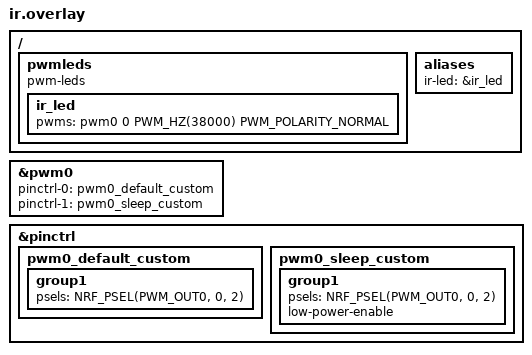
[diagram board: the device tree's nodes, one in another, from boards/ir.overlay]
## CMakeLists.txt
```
cmake_minimum_required(VERSION 3.20.0)
find_package(Zephyr REQUIRED HINTS $ENV{ZEPHYR_BASE})

project(node)

target_include_directories(app PRIVATE lib)

target_sources(app PRIVATE
    src/main.c
    lib/thread/thread.c
    lib/battery/battery.c
)
target_sources_ifdef(CONFIG_BLINKY app PRIVATE lib/blinky/blinky.c)
target_sources_ifdef(CONFIG_THREAD_STATUS_LED app PRIVATE lib/thread_status_led/thread_status_led.c)
target_sources_ifdef(CONFIG_BLINKY_THREAD app PRIVATE lib/blinky_thread/blinky_thread.c)

if(CONFIG_IR_VOLTAS OR CONFIG_IR_TECO)
    target_sources(app PRIVATE lib/ir/ir.c)
endif()

target_sources_ifdef(CONFIG_IR_VOLTAS app PRIVATE lib/ir/voltas.c)
target_sources_ifdef(CONFIG_IR_TECO app PRIVATE lib/ir/teco.c)
```

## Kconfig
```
mainmenu "Things Node"

config BLINKY
	bool "Enable blinky test mode"
	default n

config THREAD_HOSTNAME
	string "SRP hostname to register on the Thread network"
	default "thing"
	help
	  Registered via SRP once attached, so this device becomes
	  reachable as <hostname>.local from your LAN instead of needing
	  to know its Thread-assigned IPv6 address.

config THREAD_ANNOUNCE_ADDR
	string "IPv6 address to UDP-announce addresses to (debug)"
	default "fd2c:6656:1f1a:34af:4a4d:7eff:feed:5301"
	help
	  Every non-link-local IPv6 address this device gets is sent as a
	  plain UDP text message here whenever it changes - lets you
	  discover the node's reachable address without needing console
	  access. Defaults to hermes; override per build type, or set to
	  "" to disable.

config THREAD_ANNOUNCE_PORT
	int "UDP port for address announce"
	default 5555

config THING_CAPS
	string "Capability set advertised in the SRP service's TXT record"
	default ""
	help
	  Comma-separated capability tags (e.g. "ac_climate,battery"),
	  published as a single "caps" key in the _coap._udp SRP service's
	  TXT record. Lets a generic Home Assistant integration discover
	  what a given node actually supports and create the matching
	  entities - a node can declare more than one (e.g. a future board
	  mixing a PIR with a temp/humidity sensor: "pir,temp,humidity").
	  Set per build variant's conf fragment, not here - "" means no
	  capability declared.

config THING_CONFIG
	string "Extra per-node config, advertised in the SRP service's TXT record"
	default ""
	help
	  Comma-separated key=value pairs (e.g. "swing=v"), published as a
	  "config" key in the _coap._udp SRP service's TXT record - separate
	  from CONFIG_THING_CAPS on purpose: caps says which entity platforms
	  a node needs (drives PLATFORMS_BY_CAP on the HA side), this says how
	  an already-declared capability should behave for this specific
	  physical unit (e.g. which swing axis a real motor exists for, since
	  two nodes can both declare "ac_climate" but only one has a vertical
	  swing motor and the other only horizontal). Set per build variant's
	  conf fragment, not here - "" means no extra config.

config THREAD_STATUS_LED
	bool "RGB LED indicates Thread attach status"
	default y
	help
	  Blinks the onboard RGB LED red every 2s while attaching to
	  Thread (gives up after 60s to save battery), then solid blue
	  for 3s once attached. On by default for every build that has
	  Thread enabled (i.e. everything except CONFIG_BLINKY); disable
	  per build type in its conf fragment if not wanted.

config BLINKY_THREAD
	bool "Enable blinky+Thread test profile"
	default n
	help
	  Debug RGB LED control over Thread CoAP (POST /led) — on/off/
	  color. Unlike CONFIG_BLINKY, this runs alongside Thread rather
	  than blocking forever.

menu "IR Dialect"

config IR_VOLTAS
	bool "Voltas AC"
	default n
	help
	  Enable Voltas AC IR dialect.

config IR_TECO
	bool "Teco AC"
	default n
	help
	  Enable Teco AC IR dialect.

endmenu

source "Kconfig.zephyr"
```

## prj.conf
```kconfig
CONFIG_BUILD_OUTPUT_UF2=y

# OpenThread - Sleepy End Device (present on every node by default)
CONFIG_NETWORKING=y
CONFIG_NET_L2_OPENTHREAD=y
CONFIG_OPENTHREAD_MTD=y
CONFIG_OPENTHREAD_MTD_SED=y
CONFIG_OPENTHREAD_POLL_PERIOD=500
CONFIG_OPENTHREAD_MANUAL_START=y
CONFIG_OPENTHREAD_COAP=y
CONFIG_NET_IPV6=y
CONFIG_NET_UDP=y
CONFIG_NET_SOCKETS=y
CONFIG_OPENTHREAD_SLAAC=y
CONFIG_OPENTHREAD_SRP_CLIENT=y

# Reboot on any unrecoverable fault (stack overflow, hard fault, etc.)
# instead of Zephyr's default silent halt. Without this, any crash is a
# permanent hang requiring a manual power cycle - no watchdog either, so
# there's currently zero self-recovery on this node.
CONFIG_RESET_ON_FATAL_ERROR=y

# Power management - CONFIG_PM (system-level) removed 2026-08-16. nRF52 never
# selects HAS_PM (see soc/nordic/nrf52/Kconfig) - CONFIG_PM is silently forced
# back to n on this SoC regardless of this file, which is exactly the
# "assigned y, but got n" Kconfig warning that flagged this. Confirmed by
# measurement too: console-off + dropping CONFIG_PM only moved idle draw from
# ~8mA to 7.44mA, nowhere near the µA range PM would have implied if it worked.
#
# Real culprit: this board's onboard QSPI NOR flash (p25q16h, see
# node/boards/xiao_ble_nrf52840.overlay) is unused by this app (settings live
# on internal flash - see pm_static.yml) but stays powered/active by default.
# CONFIG_PM_DEVICE_RUNTIME is independent of CONFIG_PM/HAS_PM - it's the
# explicit get/put-refcounted path, not the idle-triggered one - and the
# nrf_qspi_nor driver already calls it around every access + implements a
# real suspend (enter deep-power-down, pinctrl sleep state). Combined with
# the `zephyr,pm-device-runtime-auto` DT property on the flash node, it
# should settle into DPD after the one-time init access and stay there.
CONFIG_PM_DEVICE=y
CONFIG_PM_DEVICE_RUNTIME=y

# No physical console is ever connected to this node (reverted early in the
# project) - CONFIG_PRINTK=y was still keeping the UART peripheral powered
# for a console nothing listens to. Nordic's own power-optimization guide
# measures this at ~470uA average just for that - pure waste here.
# Also disable the console subsystem itself (board default still wires it to
# a UART device) - otherwise it dangles a reference to the now-gone UART
# device at link time.a
CONFIG_SERIAL=n
CONFIG_CONSOLE=n
CONFIG_UART_CONSOLE=n

# 2026-08-16: the above three did NOT touch the real console path on this
# board. xiao_ble's devicetree wires `zephyr,console` to a USB CDC-ACM
# virtual UART, not a physical one (boards/common/usb/cdc_acm_serial.dtsi) -
# a separate subsystem gated by different Kconfig, defaulted on regardless of
# CONFIG_SERIAL/CONSOLE: `USB_DEVICE_STACK_NEXT` and
# `CDC_ACM_SERIAL_INITIALIZE_AT_BOOT` both `default y if !MCUBOOT` (see
# boards/common/usb/Kconfig.cdc_acm_serial.defconfig), and this build has no
# MCUboot. So the full USB device stack + its thread + the CDC-ACM class have
# been running through every measurement so far (~8mA, then 7.44mA, then
# 7.45mA) completely unaffected by any fix above - this is very likely the
# real dominant draw, not QSPI. Explicit override, since a plain default
# can't be beaten any other way:
CONFIG_USB_DEVICE_STACK_NEXT=n
CONFIG_CDC_ACM_SERIAL_INITIALIZE_AT_BOOT=n

# Stack / heap for networking
CONFIG_MAIN_STACK_SIZE=4096
CONFIG_SYSTEM_WORKQUEUE_STACK_SIZE=2048
CONFIG_HEAP_MEM_POOL_SIZE=8192

# Battery voltage over CoAP GET /battery - see node/lib/battery/battery.c
# and node/boards/xiao_ble_nrf52840.overlay for the VDD-as-battery ADC setup.
CONFIG_ADC=y

# OTA firmware updates via mcumgr, over UDP - rides straight over the
# Thread mesh's existing IPv6 connectivity (see hub/docs/border-router-
# native.md), no BLE/USB proximity needed. IPv6-only: this node has no
# IPv4 stack, and CONFIG_MCUMGR_TRANSPORT_UDP_IPV4 depends on CONFIG_NET_IPV4
# so it's already forced off without needing to say so here. img_mgmt talks
# to MCUboot's slot0/slot1 (see node/boards/mcuboot_partitions.overlay);
# os_mgmt is what provides the "reset" command used to trigger the
# slot swap after a test image is uploaded.
CONFIG_ZCBOR=y
CONFIG_STREAM_FLASH=y
CONFIG_MCUMGR=y
CONFIG_MCUMGR_TRANSPORT_UDP=y
CONFIG_MCUMGR_TRANSPORT_UDP_IPV6=y
CONFIG_IMG_MANAGER=y
CONFIG_MCUMGR_GRP_IMG=y
CONFIG_MCUMGR_GRP_OS=y
```

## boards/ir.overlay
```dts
/ {
	pwmleds {
		compatible = "pwm-leds";
		ir_led: ir_led {
			pwms = <&pwm0 0 PWM_HZ(38000) PWM_POLARITY_NORMAL>;
		};
	};

	aliases {
		ir-led = &ir_led;
	};
};

&pwm0 {
	status = "okay";
	pinctrl-0 = <&pwm0_default_custom>;
	pinctrl-1 = <&pwm0_sleep_custom>;
	pinctrl-names = "default", "sleep";
};

&pinctrl {
	pwm0_default_custom: pwm0_default_custom {
		group1 {
			psels = <NRF_PSEL(PWM_OUT0, 0, 2)>;
		};
	};

	pwm0_sleep_custom: pwm0_sleep_custom {
		group1 {
			psels = <NRF_PSEL(PWM_OUT0, 0, 2)>;
			low-power-enable;
		};
	};
};
```

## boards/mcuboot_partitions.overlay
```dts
/*
 * MCUboot-ready flash layout, shared by both the app image and the mcuboot
 * image itself (wired in via node/sysbuild/CMakeLists.txt) - both need the
 * same boot_partition/slot0_partition/slot1_partition nodelabels to agree
 * on where things physically live.
 *
 * Replaces the board's default single-image layout (sized for the factory
 * Adafruit UF2 bootloader - see nrf52840_partition_uf2_sdv7.dtsi in the
 * Zephyr tree) with the standard MCUboot layout used elsewhere in the
 * Zephyr tree for a bare nRF52840 (dts/vendor/nordic/nrf52840_partition.dtsi,
 * same numbers): mcuboot + two equal app slots for swap-with-revert OTA +
 * storage. This node is only ever flashed via SWD now, so there's no
 * remaining reason to preserve compatibility with the factory bootloader's
 * layout or its UF2 partition.
 *
 * Sizing: two 0x76000 (472KB) slots vs. the current single-image firmware's
 * actual flash usage of ~247KB (see PROGRESS.md /
 * arm-zephyr-eabi-size on a real build) - just under 2x headroom per slot
 * for growth.
 */
/ {
	chosen {
		/* Board default points this at the old single "code_partition",
		 * which /delete-node/ below removes along with the rest of the
		 * old layout - the app now boots from slot0, not directly from
		 * a fixed spot past a SoftDevice-shaped gap.
		 */
		zephyr,code-partition = &slot0_partition;
	};
};

&flash0 {
	/delete-node/ partitions;

	partitions {
		compatible = "fixed-partitions";
		#address-cells = <1>;
		#size-cells = <1>;

		boot_partition: partition@0 {
			label = "mcuboot";
			reg = <0x00000000 0x0000C000>;
			read-only;
		};

		slot0_partition: partition@c000 {
			label = "image-0";
			reg = <0x0000C000 0x00076000>;
		};

		slot1_partition: partition@82000 {
			label = "image-1";
			reg = <0x00082000 0x00076000>;
		};

		storage_partition: partition@f8000 {
			label = "storage";
			reg = <0x000F8000 0x00008000>;
		};
	};
};
```

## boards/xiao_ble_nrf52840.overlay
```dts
/*
 * The onboard QSPI NOR flash (p25q16h) is unused by this app - the
 * settings_storage partition lives on internal flash (see the board's
 * pm_static.yml). Left at its power-on default it just sits there powered
 * and active, drawing current for nothing. This DT property is what actually
 * triggers pm_device_runtime_enable() for it after init (see
 * include/zephyr/pm/device.h's DT_PROP_OR(..., zephyr_pm_device_runtime_auto)
 * check in kernel/device.c) - the driver (drivers/flash/nrf_qspi_nor.c)
 * already calls pm_device_runtime_get()/put_async() around every access and
 * implements a real suspend (deep-power-down + pinctrl sleep state), it just
 * needs runtime PM switched on for this instance. Requires
 * CONFIG_PM_DEVICE=y + CONFIG_PM_DEVICE_RUNTIME=y in prj.conf.
 */
&p25q16h {
	zephyr,pm-device-runtime-auto;
};

/*
 * Battery voltage. This node's coin cell is wired directly to 3V3/GND (no
 * regulator, no BQ25101 in that path) - so VDD *is* the battery voltage,
 * measurable via the SAADC's internal VDD channel with no extra pin and no
 * extra current draw beyond the one-shot conversion itself. (The board's
 * own onboard divider circuit on P0.14/P0.31 taps VBAT - the charge IC's
 * input net - which is unconnected in this wiring, so that path doesn't
 * apply here.) Config mirrors Zephyr's own adc_dt sample
 * (samples/drivers/adc/adc_dt/boards/nrf52840dk_nrf52840.overlay,
 * channel@1): internal 0.6V reference + 1/6 gain = 3.6V full scale, well
 * above a fresh CR2032's ~3.3V and comfortably covering its full discharge
 * range. See node/lib/battery/battery.c.
 */
#include <zephyr/dt-bindings/adc/adc.h>
#include <zephyr/dt-bindings/adc/nrf-saadc.h>

/ {
	zephyr,user {
		io-channels = <&adc 1>;
	};
};

&adc {
	#address-cells = <1>;
	#size-cells = <0>;

	channel@1 {
		reg = <1>;
		zephyr,gain = "ADC_GAIN_1_6";
		zephyr,reference = "ADC_REF_INTERNAL";
		zephyr,acquisition-time = <ADC_ACQ_TIME_DEFAULT>;
		zephyr,input-positive = <NRF_SAADC_VDD>;
		zephyr,resolution = <14>;
		zephyr,oversampling = <8>;
	};
};
```

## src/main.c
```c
#include <zephyr/kernel.h>

#include "battery/battery.h"
#include "blinky/blinky.h"
#include "blinky_thread/blinky_thread.h"
#include "ir/ir.h"
#include "thread/thread.h"
#include "thread_status_led/thread_status_led.h"

int main(void)
{
#if defined(CONFIG_BLINKY)
	init_blinky();
#endif

	thread_init();
	battery_init();

#if defined(CONFIG_THREAD_STATUS_LED)
	thread_status_led_init();
#endif

#if defined(CONFIG_BLINKY_THREAD)
	blinky_thread_init();
#endif

#if defined(CONFIG_IR_VOLTAS) || defined(CONFIG_IR_TECO)
	ir_init();
#endif

	return 0;
}
```

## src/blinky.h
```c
#ifndef BLINKY_H
#define BLINKY_H

/* Blocks forever toggling the onboard LED. Never returns. */
void init_blinky(void);

#endif
```
